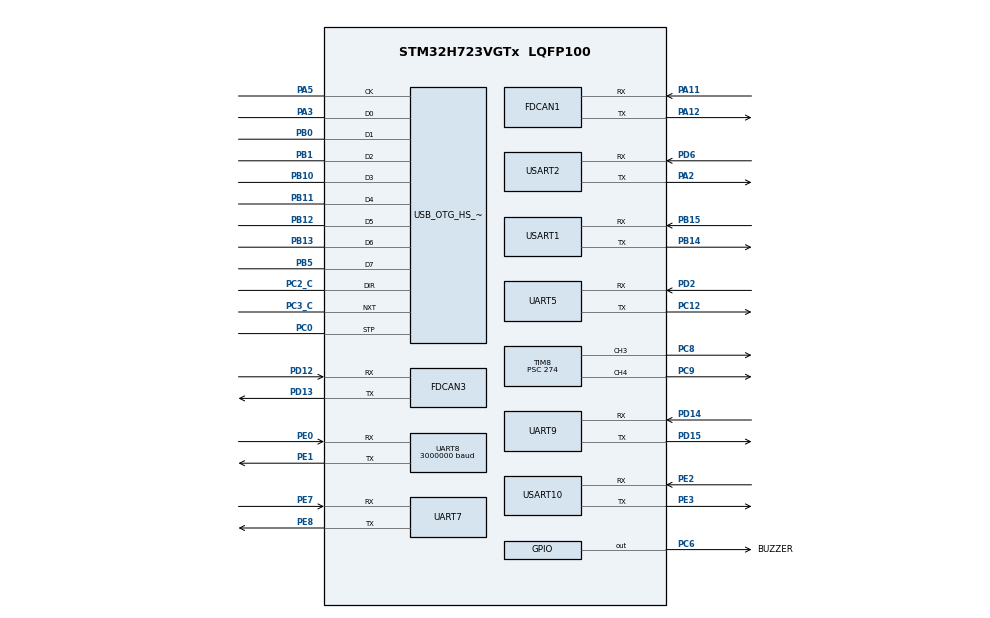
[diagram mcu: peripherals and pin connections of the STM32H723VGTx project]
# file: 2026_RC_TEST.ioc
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CORTEX_M7.default_mode_Activation=1
Dma.Request0=UART8_RX
Dma.Request1=UART8_TX
Dma.UART8_RX.0.Direction=DMA_PERIPH_TO_MEMORY
Dma.UART8_RX.0.EventEnable=DISABLE
Dma.UART8_RX.0.FIFOMode=DMA_FIFOMODE_DISABLE
Dma.UART8_RX.0.Instance=DMA1_Stream0
Dma.UART8_RX.0.MemDataAlignment=DMA_MDATAALIGN_BYTE
Dma.UART8_RX.0.MemInc=DMA_MINC_ENABLE
Dma.UART8_RX.0.Mode=DMA_NORMAL
Dma.UART8_RX.0.PeriphDataAlignment=DMA_PDATAALIGN_BYTE
Dma.UART8_RX.0.PeriphInc=DMA_PINC_DISABLE
Dma.UART8_RX.0.Polarity=HAL_DMAMUX_REQ_GEN_RISING
Dma.UART8_RX.0.Priority=DMA_PRIORITY_HIGH
Dma.UART8_RX.0.RequestNumber=1
Dma.UART8_RX.0.SignalID=NONE
Dma.UART8_RX.0.SyncEnable=DISABLE
Dma.UART8_RX.0.SyncPolarity=HAL_DMAMUX_SYNC_NO_EVENT
Dma.UART8_RX.0.SyncRequestNumber=1
Dma.UART8_RX.0.SyncSignalID=NONE
Dma.UART8_TX.1.Direction=DMA_MEMORY_TO_PERIPH
Dma.UART8_TX.1.EventEnable=DISABLE
Dma.UART8_TX.1.FIFOMode=DMA_FIFOMODE_DISABLE
Dma.UART8_TX.1.Instance=DMA1_Stream1
Dma.UART8_TX.1.MemDataAlignment=DMA_MDATAALIGN_BYTE
Dma.UART8_TX.1.MemInc=DMA_MINC_ENABLE
Dma.UART8_TX.1.Mode=DMA_NORMAL
Dma.UART8_TX.1.PeriphDataAlignment=DMA_PDATAALIGN_BYTE
Dma.UART8_TX.1.PeriphInc=DMA_PINC_DISABLE
Dma.UART8_TX.1.Polarity=HAL_DMAMUX_REQ_GEN_RISING
Dma.UART8_TX.1.Priority=DMA_PRIORITY_HIGH
Dma.UART8_TX.1.RequestNumber=1
Dma.UART8_TX.1.SignalID=NONE
Dma.UART8_TX.1.SyncEnable=DISABLE
Dma.UART8_TX.1.SyncPolarity=HAL_DMAMUX_SYNC_NO_EVENT
Dma.UART8_TX.1.SyncRequestNumber=1
Dma.UART8_TX.1.SyncSignalID=NONE
FDCAN1.AutoRetransmission=ENABLE
FDCAN1.CalculateBaudRateNominal=1000000
FDCAN1.CalculateTimeBitNominal=1000
FDCAN1.CalculateTimeQuantumNominal=62.5
FDCAN1.DataSyncJumpWidth=2
FDCAN1.DataTimeSeg1=13
FDCAN1.DataTimeSeg2=2
FDCAN1.ExtFiltersNbr=1
FDCAN1.FrameFormat=FDCAN_FRAME_FD_BRS
FDCAN1.NominalPrescaler=2
FDCAN1.NominalSyncJumpWidth=2
FDCAN1.NominalTimeSeg1=13
FDCAN1.NominalTimeSeg2=2
FDCAN1.RxBufferSize=FDCAN_DATA_BYTES_64
FDCAN1.RxFifo0ElmtSize=FDCAN_DATA_BYTES_64
FDCAN1.RxFifo0ElmtsNbr=16
FDCAN1.RxFifo1ElmtSize=FDCAN_DATA_BYTES_64
FDCAN1.StdFiltersNbr=1
FDCAN1.TxElmtSize=FDCAN_DATA_BYTES_64
FDCAN1.TxFifoQueueElmtsNbr=32
FDCAN3.AutoRetransmission=ENABLE
FDCAN3.CalculateBaudRateNominal=1000000
FDCAN3.CalculateTimeBitNominal=1000
FDCAN3.CalculateTimeQuantumNominal=62.5
FDCAN3.DataSyncJumpWidth=2
FDCAN3.DataTimeSeg1=13
FDCAN3.DataTimeSeg2=2
FDCAN3.ExtFiltersNbr=1
FDCAN3.FrameFormat=FDCAN_FRAME_FD_BRS
FDCAN3.MessageRAMOffset=0x500
FDCAN3.NominalPrescaler=2
FDCAN3.NominalSyncJumpWidth=2
FDCAN3.NominalTimeSeg1=13
FDCAN3.NominalTimeSeg2=2
FDCAN3.RxFifo0ElmtSize=FDCAN_DATA_BYTES_64
FDCAN3.RxFifo1ElmtSize=FDCAN_DATA_BYTES_64
FDCAN3.RxFifo1ElmtsNbr=16
FDCAN3.StdFiltersNbr=1
FDCAN3.TxElmtSize=FDCAN_DATA_BYTES_64
FDCAN3.TxFifoQueueElmtsNbr=32
FREERTOS.Tasks01=defaultTask,24,1024,StartDefaultTask,Default,NULL,Dynamic,NULL,NULL
FREERTOS.configCHECK_FOR_STACK_OVERFLOW=2
FREERTOS.configENABLE_FPU=1
FREERTOS.configTOTAL_HEAP_SIZE=65536
FREERTOS.configUSE_MALLOC_FAILED_HOOK=1
Mcu.Family=STM32H7
Mcu.Name=STM32H723VGTx
Mcu.Package=LQFP100
NVIC.DMA1_Stream0_IRQn=true\:5\:0\:false\:false\:true\:true\:false\:true\:true
NVIC.DMA1_Stream1_IRQn=true\:5\:0\:false\:false\:true\:true\:false\:true\:true
NVIC.FDCAN1_IT0_IRQn=true\:5\:0\:false\:false\:true\:true\:true\:true\:true
NVIC.FDCAN3_IT0_IRQn=true\:5\:0\:false\:false\:true\:true\:true\:true\:true
NVIC.OTG_HS_IRQn=true\:5\:0\:false\:false\:true\:true\:false\:true\:true
NVIC.PriorityGroup=NVIC_PRIORITYGROUP_4
NVIC.TIM1_UP_IRQn=true\:15\:0\:false\:false\:true\:false\:false\:true\:true
NVIC.TIM3_IRQn=true\:5\:0\:false\:false\:true\:true\:true\:true\:true
NVIC.TimeBase=TIM1_UP_IRQn
NVIC.TimeBaseIP=TIM1
NVIC.UART5_IRQn=true\:5\:0\:false\:false\:true\:true\:true\:true\:true
NVIC.UART7_IRQn=true\:5\:0\:false\:false\:true\:true\:true\:true\:true
NVIC.UART8_IRQn=true\:5\:0\:false\:false\:true\:true\:true\:true\:true
NVIC.UART9_IRQn=true\:5\:0\:false\:false\:true\:true\:true\:true\:true
NVIC.USART10_IRQn=true\:5\:0\:false\:false\:true\:true\:true\:true\:true
NVIC.USART1_IRQn=true\:5\:0\:false\:false\:true\:true\:true\:true\:true
NVIC.USART2_IRQn=true\:5\:0\:false\:false\:true\:true\:true\:true\:true
PA11.GPIO_Speed=GPIO_SPEED_FREQ_VERY_HIGH
PA11.Mode=FDCAN_Activate
PA11.Signal=FDCAN1_RX
PA12.GPIO_Speed=GPIO_SPEED_FREQ_VERY_HIGH
PA12.Mode=FDCAN_Activate
PA12.Signal=FDCAN1_TX
PA13(JTMS/SWDIO).Mode=Serial_Wire
PA13(JTMS/SWDIO).Signal=DEBUG_JTMS-SWDIO
PA14(JTCK/SWCLK).Mode=Serial_Wire
PA14(JTCK/SWCLK).Signal=DEBUG_JTCK-SWCLK
PA2.GPIO_PuPd=GPIO_PULLUP
PA2.Mode=Asynchronous
PA2.Signal=USART2_TX
PA3.Mode=Device_HS
PA3.Signal=USB_OTG_HS_ULPI_D0
PA5.Mode=Device_HS
PA5.Signal=USB_OTG_HS_ULPI_CK
PB0.Mode=Device_HS
PB0.Signal=USB_OTG_HS_ULPI_D1
PB1.Mode=Device_HS
PB1.Signal=USB_OTG_HS_ULPI_D2
PB10.Mode=Device_HS
PB10.Signal=USB_OTG_HS_ULPI_D3
PB11.Mode=Device_HS
PB11.Signal=USB_OTG_HS_ULPI_D4
PB12.Mode=Device_HS
PB12.Signal=USB_OTG_HS_ULPI_D5
PB13.Mode=Device_HS
PB13.Signal=USB_OTG_HS_ULPI_D6
PB14.GPIO_PuPd=GPIO_PULLUP
PB14.Mode=Asynchronous
PB14.Signal=USART1_TX
PB15.GPIO_PuPd=GPIO_PULLUP
PB15.Mode=Asynchronous
PB15.Signal=USART1_RX
PB5.Mode=Device_HS
PB5.Signal=USB_OTG_HS_ULPI_D7
PC0.Mode=Device_HS
PC0.Signal=USB_OTG_HS_ULPI_STP
PC12.GPIO_PuPd=GPIO_PULLUP
PC12.Mode=Asynchronous
PC12.Signal=UART5_TX
PC2_C.Mode=Device_HS
PC2_C.Signal=USB_OTG_HS_ULPI_DIR
PC3_C.Mode=Device_HS
PC3_C.Signal=USB_OTG_HS_ULPI_NXT
PC6.GPIO_Label=BUZZER
PC6.Signal=GPIO_Output
PC8.Signal=S_TIM8_CH3
PC9.Signal=S_TIM8_CH4
PD12.GPIO_Speed=GPIO_SPEED_FREQ_VERY_HIGH
PD12.Mode=FDCAN_Activate
PD12.Signal=FDCAN3_RX
PD13.GPIO_Speed=GPIO_SPEED_FREQ_VERY_HIGH
PD13.Mode=FDCAN_Activate
PD13.Signal=FDCAN3_TX
PD14.GPIO_PuPd=GPIO_PULLUP
PD14.Mode=Asynchronous
PD14.Signal=UART9_RX
PD15.GPIO_PuPd=GPIO_PULLUP
PD15.Mode=Asynchronous
PD15.Signal=UART9_TX
PD2.GPIO_PuPd=GPIO_PULLUP
PD2.Mode=Asynchronous
PD2.Signal=UART5_RX
PD6.GPIO_PuPd=GPIO_PULLUP
PD6.Mode=Asynchronous
PD6.Signal=USART2_RX
PE0.GPIO_Speed=GPIO_SPEED_FREQ_VERY_HIGH
PE0.Mode=Asynchronous
PE0.Signal=UART8_RX
PE1.GPIO_Speed=GPIO_SPEED_FREQ_VERY_HIGH
PE1.Mode=Asynchronous
PE1.Signal=UART8_TX
PE2.GPIO_PuPd=GPIO_PULLUP
PE2.Mode=Asynchronous
PE2.Signal=USART10_RX
PE3.GPIO_PuPd=GPIO_PULLUP
PE3.Mode=Asynchronous
PE3.Signal=USART10_TX
PE7.GPIO_PuPd=GPIO_PULLUP
PE7.Mode=Asynchronous
PE7.Signal=UART7_RX
PE8.GPIO_PuPd=GPIO_PULLUP
PE8.Mode=Asynchronous
PE8.Signal=UART7_TX
PH0-OSC_IN.Mode=HSE-External-Oscillator
PH0-OSC_IN.Signal=RCC_OSC_IN
PH1-OSC_OUT.Mode=HSE-External-Oscillator
PH1-OSC_OUT.Signal=RCC_OSC_OUT
ProjectManager.HeapSize=0x200
ProjectManager.StackSize=0x400
ProjectManager.TargetToolchain=CMake
RCC.ADCFreq_Value=85000000
RCC.APB1Freq_Value=137500000
RCC.APB2Freq_Value=137500000
RCC.APB3Freq_Value=137500000
RCC.APB4Freq_Value=137500000
RCC.CortexFreq_Value=550000000
RCC.D1PPRE=RCC_APB3_DIV2
RCC.D2PPRE1=RCC_APB1_DIV2
RCC.D2PPRE2=RCC_APB2_DIV2
RCC.D3PPRE=RCC_APB4_DIV2
RCC.DIVM1=2
RCC.DIVN1=34
RCC.DIVN2=170
RCC.DIVP1=1
RCC.FDCANCLockSelection=RCC_FDCANCLKSOURCE_HSE
RCC.HCLKFreq_Value=275000000
RCC.HPRE=RCC_HCLK_DIV2
RCC.HSE_VALUE=32000000
RCC.PLL2FRACN=0
RCC.PLL3FRACN=0
RCC.PLLFRACN=3072
RCC.PLLSourceVirtual=RCC_PLLSOURCE_HSE
RCC.SYSCLKFreq_VALUE=550000000
RCC.SYSCLKSource=RCC_SYSCLKSOURCE_PLLCLK
RCC.USBCLockSelection=RCC_USBCLKSOURCE_HSI48
RCC.USBFreq_Value=48000000
SH.S_TIM8_CH3.0=TIM8_CH3,PWM Generation3 CH3
SH.S_TIM8_CH4.0=TIM8_CH4,PWM Generation4 CH4
TIM3.Period=1000-1
TIM3.Prescaler=275-1
TIM8.Channel-PWM\ Generation3\ CH3=TIM_CHANNEL_3
TIM8.Channel-PWM\ Generation4\ CH4=TIM_CHANNEL_4
TIM8.Period=1999
TIM8.Prescaler=274
UART8.BaudRate=3000000
USART1.VirtualMode-Asynchronous=VM_ASYNC
USART10.VirtualMode=VM_ASYNC
USART2.VirtualMode-Asynchronous=VM_ASYNC
USB_DEVICE.CLASS_NAME_HS=CDC
USB_DEVICE.MANUFACTURER_STRING=ACTION
USB_DEVICE.PRODUCT_STRING_CDC_HS=ACTION MCU
USB_DEVICE.VirtualMode=Cdc
USB_DEVICE.VirtualModeHS=Cdc_HS
USB_OTG_HS.VirtualMode-Device_HS=Device_HS
VP_FREERTOS_VS_CMSIS_V2.Mode=CMSIS_V2
VP_MEMORYMAP_VS_MEMORYMAP.Mode=CurAppReg
VP_SYS_VS_tim1.Mode=TIM1
VP_TIM3_VS_ClockSourceINT.Mode=Internal
VP_TIM8_VS_ClockSourceINT.Mode=Internal
VP_USB_DEVICE_VS_USB_DEVICE_CDC_HS.Mode=CDC_HS
board=custom

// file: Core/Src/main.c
/* USER CODE BEGIN Header */
/**
  ******************************************************************************
  * @file           : main.c
  * @brief          : Main program body
  ******************************************************************************
  * @attention
  *
  * Copyright (c) 2026 STMicroelectronics.
  * All rights reserved.
  *
  * This software is licensed under terms that can be found in the LICENSE file
  * in the root directory of this software component.
  * If no LICENSE file comes with this software, it is provided AS-IS.
  *
  ******************************************************************************
  */
/* USER CODE END Header */
#include "main.h"
#include "FreeRTOS.h"
#include "cmsis_os2.h"
#include "dma.h"
#include "fdcan.h"
#include "tim.h"
#include "usart.h"
#include "usb_device.h"
#include "gpio.h"

void SystemClock_Config(void);
static void MPU_Config(void);
void MX_FREERTOS_Init(void);

int main(void)
{

  /* MPU Configuration--------------------------------------------------------*/
  MPU_Config();

  /* MCU Configuration--------------------------------------------------------*/

  /* Reset of all peripherals, Initializes the Flash interface and the Systick. */
  HAL_Init();

  /* Configure the system clock */
  SystemClock_Config();

  /* Initialize all configured peripherals */
  MX_GPIO_Init();
  MX_DMA_Init();
  MX_FDCAN1_Init();
  MX_FDCAN3_Init();
  MX_TIM3_Init();
  MX_UART8_Init();
  MX_TIM8_Init();
  MX_UART5_Init();
  MX_UART7_Init();
  MX_UART9_Init();
  MX_USART1_UART_Init();
  MX_USART2_UART_Init();
  MX_USART10_UART_Init();

  /* Init scheduler */
  osKernelInitialize();  /* Call init function for freertos objects (in cmsis_os2.c) */
  MX_FREERTOS_Init();

  /* Start scheduler */
  osKernelStart();

  /* We should never get here as control is now taken by the scheduler */

  /* Infinite loop */
  while (1)
  {

  }
}

void SystemClock_Config(void)
{
  RCC_OscInitTypeDef RCC_OscInitStruct = {0};
  RCC_ClkInitTypeDef RCC_ClkInitStruct = {0};

  /** Supply configuration update enable
  */
  HAL_PWREx_ConfigSupply(PWR_LDO_SUPPLY);

  /** Configure the main internal regulator output voltage
  */
  __HAL_PWR_VOLTAGESCALING_CONFIG(PWR_REGULATOR_VOLTAGE_SCALE0);

  while(!__HAL_PWR_GET_FLAG(PWR_FLAG_VOSRDY)) {}

  /** Initializes the RCC Oscillators according to the specified parameters
  * in the RCC_OscInitTypeDef structure.
  */
  RCC_OscInitStruct.OscillatorType = RCC_OSCILLATORTYPE_HSI48|RCC_OSCILLATORTYPE_HSE;
  RCC_OscInitStruct.HSEState = RCC_HSE_ON;
  RCC_OscInitStruct.HSI48State = RCC_HSI48_ON;
  RCC_OscInitStruct.PLL.PLLState = RCC_PLL_ON;
  RCC_OscInitStruct.PLL.PLLSource = RCC_PLLSOURCE_HSE;
  RCC_OscInitStruct.PLL.PLLM = 2;
  RCC_OscInitStruct.PLL.PLLN = 34;
  RCC_OscInitStruct.PLL.PLLP = 1;
  RCC_OscInitStruct.PLL.PLLQ = 2;
  RCC_OscInitStruct.PLL.PLLR = 2;
  RCC_OscInitStruct.PLL.PLLRGE = RCC_PLL1VCIRANGE_3;
  RCC_OscInitStruct.PLL.PLLVCOSEL = RCC_PLL1VCOWIDE;
  RCC_OscInitStruct.PLL.PLLFRACN = 3072;
  if (HAL_RCC_OscConfig(&RCC_OscInitStruct) != HAL_OK)
  {
    Error_Handler();
  }

  /** Initializes the CPU, AHB and APB buses clocks
  */
  RCC_ClkInitStruct.ClockType = RCC_CLOCKTYPE_HCLK|RCC_CLOCKTYPE_SYSCLK
                              |RCC_CLOCKTYPE_PCLK1|RCC_CLOCKTYPE_PCLK2
                              |RCC_CLOCKTYPE_D3PCLK1|RCC_CLOCKTYPE_D1PCLK1;
  RCC_ClkInitStruct.SYSCLKSource = RCC_SYSCLKSOURCE_PLLCLK;
  RCC_ClkInitStruct.SYSCLKDivider = RCC_SYSCLK_DIV1;
  RCC_ClkInitStruct.AHBCLKDivider = RCC_HCLK_DIV2;
  RCC_ClkInitStruct.APB3CLKDivider = RCC_APB3_DIV2;
  RCC_ClkInitStruct.APB1CLKDivider = RCC_APB1_DIV2;
  RCC_ClkInitStruct.APB2CLKDivider = RCC_APB2_DIV2;
  RCC_ClkInitStruct.APB4CLKDivider = RCC_APB4_DIV2;

  if (HAL_RCC_ClockConfig(&RCC_ClkInitStruct, FLASH_LATENCY_3) != HAL_OK)
  {
    Error_Handler();
  }
}

 /* MPU Configuration */

void MPU_Config(void)
{
  MPU_Region_InitTypeDef MPU_InitStruct = {0};

  /* Disables the MPU */
  HAL_MPU_Disable();

  /** Initializes and configures the Region and the memory to be protected
  */
  MPU_InitStruct.Enable = MPU_REGION_ENABLE;
  MPU_InitStruct.Number = MPU_REGION_NUMBER0;
  MPU_InitStruct.BaseAddress = 0x0;
  MPU_InitStruct.Size = MPU_REGION_SIZE_4GB;
  MPU_InitStruct.SubRegionDisable = 0x87;
  MPU_InitStruct.TypeExtField = MPU_TEX_LEVEL0;
  MPU_InitStruct.AccessPermission = MPU_REGION_NO_ACCESS;
  MPU_InitStruct.DisableExec = MPU_INSTRUCTION_ACCESS_DISABLE;
  MPU_InitStruct.IsShareable = MPU_ACCESS_SHAREABLE;
  MPU_InitStruct.IsCacheable = MPU_ACCESS_NOT_CACHEABLE;
  MPU_InitStruct.IsBufferable = MPU_ACCESS_NOT_BUFFERABLE;

  HAL_MPU_ConfigRegion(&MPU_InitStruct);
  /* Enables the MPU */
  HAL_MPU_Enable(MPU_PRIVILEGED_DEFAULT);

}

void HAL_TIM_PeriodElapsedCallback(TIM_HandleTypeDef *htim)
{
  if (htim->Instance == TIM1)
  {
    HAL_IncTick();
  }
}

void Error_Handler(void)
{
  __disable_irq();
  while (1)
  {
  }
}

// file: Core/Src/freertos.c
/* USER CODE BEGIN Header */
/**
  ******************************************************************************
  * File Name          : freertos.c
  * Description        : Code for freertos applications
  ******************************************************************************
  * @attention
  *
  * Copyright (c) 2026 STMicroelectronics.
  * All rights reserved.
  *
  * This software is licensed under terms that can be found in the LICENSE file
  * in the root directory of this software component.
  * If no LICENSE file comes with this software, it is provided AS-IS.
  *
  ******************************************************************************
  */
/* USER CODE END Header */

#include "FreeRTOS.h"
#include "task.h"
#include "main.h"
#include "FreeRTOS.h"
#include "cmsis_os2.h"

/* USER CODE BEGIN Includes */

#include "user_task.h"

/* USER CODE END Includes */

/* Definitions for defaultTask */
osThreadId_t defaultTaskHandle;
const osThreadAttr_t defaultTask_attributes = {
  .name = "defaultTask",
  .stack_size = 1024 * 4,
  .priority = (osPriority_t) osPriorityNormal,
};

void StartDefaultTask(void *argument);

extern void MX_USB_DEVICE_Init(void);
void MX_FREERTOS_Init(void); /* (MISRA C 2004 rule 8.1) */

/* Hook prototypes */
void vApplicationStackOverflowHook(xTaskHandle xTask, char *pcTaskName);
void vApplicationMallocFailedHook(void);

/* USER CODE BEGIN 4 */
void vApplicationStackOverflowHook(xTaskHandle xTask, char *pcTaskName)
{
   /* Run time stack overflow checking is performed if
   configCHECK_FOR_STACK_OVERFLOW is defined to 1 or 2. This hook function is
   called if a stack overflow is detected. */

  (void)xTask;
  (void)pcTaskName;

  __disable_irq();
  /* 栈溢出属于不可恢复错误：保持蜂鸣器常亮，便于现场快速判断 */
  HAL_GPIO_WritePin(BUZZER_GPIO_Port, BUZZER_Pin, GPIO_PIN_SET);
  for (;;)
  {
  }
}
/* USER CODE END 4 */

/* USER CODE BEGIN 5 */
void vApplicationMallocFailedHook(void)
{
   /* vApplicationMallocFailedHook() will only be called if
   configUSE_MALLOC_FAILED_HOOK is set to 1 in FreeRTOSConfig.h. It is a hook
   function that will get called if a call to pvPortMalloc() fails.
   pvPortMalloc() is called internally by the kernel whenever a task, queue,
   timer or semaphore is created. It is also called by various parts of the
   demo application. If heap_1.c or heap_2.c are used, then the size of the
   heap available to pvPortMalloc() is defined by configTOTAL_HEAP_SIZE in
   FreeRTOSConfig.h, and the xPortGetFreeHeapSize() API function can be used
   to query the size of free heap space that remains (although it does not
   provide information on how the remaining heap might be fragmented). */

   __disable_irq();
   /* 内存分配失败同样不可恢复：蜂鸣器 100ms/900ms 闪烁 */
   for (;;)
   {
     HAL_GPIO_WritePin(BUZZER_GPIO_Port, BUZZER_Pin, GPIO_PIN_SET);
     for (volatile uint32_t i = 0; i < 2000000U; i++) { __NOP(); }
     HAL_GPIO_WritePin(BUZZER_GPIO_Port, BUZZER_Pin, GPIO_PIN_RESET);
     for (volatile uint32_t i = 0; i < 18000000U; i++) { __NOP(); }
   }
}
/* USER CODE END 5 */

void MX_FREERTOS_Init(void) {

  /* Create the thread(s) */
  /* creation of defaultTask */
  defaultTaskHandle = osThreadNew(StartDefaultTask, NULL, &defaultTask_attributes);

}

void StartDefaultTask(void *argument)
{
  /* init code for USB_DEVICE */
  MX_USB_DEVICE_Init();
  /* USER CODE BEGIN StartDefaultTask */
  User_Task_Init();
  /* Infinite loop */
  for(;;)
  {
    osDelay(1);
  }
  /* USER CODE END StartDefaultTask */
}
